# rCSL_lcdc_001 register map
Vendor: Texas Instruments
Peripheral module from a debugger description file (folder c674x).
Registers are 32-bit, access not given, reset 0x0 unless marked. A register's access mark holds for its fields unless they carry their own. Offsets are as the file gives them; lines under a group give offsets from that group; [hi:lo] are bit positions; {n}, {i} and the like mark numbered series; 'fields as' and 'values as' point back to an identical list; <NAME> marks a mode.

## LCDC — LCD Controller
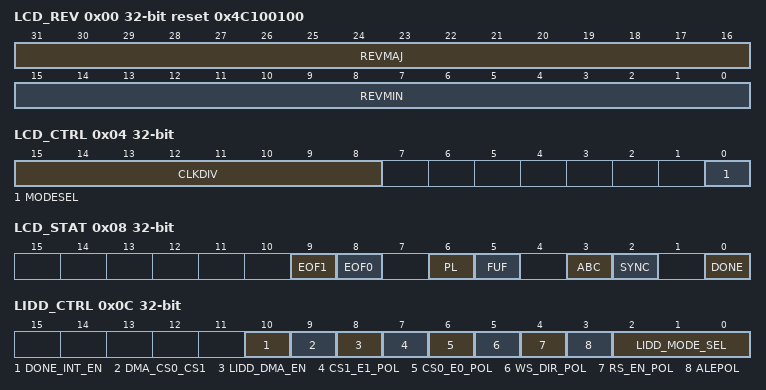
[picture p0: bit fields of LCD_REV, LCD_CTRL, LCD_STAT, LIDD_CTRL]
0x00 LCD_REV ro reset 0x4C100100 — LCD Revision Identification Register
  [31:16] REVMAJ — Peripheral Identification Number
  [15:0] REVMIN — Peripheral Identification Number
0x04 LCD_CTRL — LCD Control Register
  [15:8] CLKDIV rw — Clock Divisor
  [0] MODESEL rw — LCD Mode Select
    0=LIDD (LCD Controller in LIDD mode); 1=RASTER (LCD Controller in Raster mode)
0x08 LCD_STAT — LCD Status Register
  [9] EOF1 rw — End of Frame 1
    0=NO (No end of frame 1 detected); 1=YES (End of frame 1 detected)
  [8] EOF0 rw — End of Frame 0
    0=NO (No end of frame 0 detected); 1=YES (End of frame 0 detected)
  [6] PL rw — Loaded Palette
    0=NO (The palette is not loaded); 1=YES (The palette is loaded)
  [5] FUF rw — FIFO Underflow Status
    0=NO (FIFO has not underrun); 1=YES (LCD dither logic not supplying data to FIFO at a sufficient rate, FIFO has completely emptied and data pin driver logic has attempted to take added data from FIFO)
  [3] ABC rw — AC Bias Count Status
    0=NOT_ZERO (AC bias transition counter has not decremented to zero); 1=ZERO (AC bias transition counter has decremented to zero, indicating that the lcd_ac_o line has transitioned the number of times which is specified by the acbi control bit-field. Counter is reloaded with value in acbi but is disabled until the user clears ABC)
  [2] SYNC rw — Sync Lost
    0=NORMAL; 1=SYNC_LOST (Frame Synchronization Lost has occurred)
  [0] DONE rw — Raster or LIDD Frame Done (shared; depends on whether Raster or LIDD mode enabled)
    0=ENABLE (Raster or DMA-to-LIDD engine is enabled); 1=DISABLE (Raster or DMA-to-LIDD engine is disabled and the active frame has just completed)
0x0C LIDD_CTRL — LCD LIDD Control Register
  [10] DONE_INT_EN rw — LIDD Frame Done Interrupt Enable
    0=DISABLE (Disable LIDD Frame Done interrupt); 1=ENABLE (Enable LIDD Frame Done interrupt (seen on LCD Status Reg bit 0))
  [9] DMA_CS0_CS1 rw — CS0 CS1 Select for LIDD DMA writes
    0=WRITE_CS0 (DMA writes to LIDD CS0); 1=WRITE_CS1 (DMA writes to LIDD CS1)
  [8] LIDD_DMA_EN rw — LIDD DMA Enable
    0=DISABLE (Deactivate DMA control of LIDD interface; DMA control is released upon completion of transfer of the currentframe of data (LIDD Frame Done) after this bit is cleared. The MPU has direct read/write access to the panel in this mode); 1=ENABLE (Activate DMA to drive LIDD interface to support streaming data to smart panels. The MPU cannot access the panel directly in this mode)
  [7] CS1_E1_POL rw — Chip Select 1/Enable 1 (Secondary) Polarity Control
    0=INVERT_DISABLE (Do Not Invert Chip Select 1/Enable 1); 1=INVERT_ENABLE (Invert Chip Select 1/Enable 1 Chip Select 1 is active low by default; Enable 1 is active high by default)
  [6] CS0_E0_POL rw — Chip Select 0/Enable 0 (Primary) Polarity Control
    0=INVERT_DISABLE (Do Not Invert Chip Select 0/Enable 0); 1=INVERT_ENABLE (Invert Chip Select 0/Enable 0 Chip Select 0 is active low by default; Enable 0 is active high by default)
  [5] WS_DIR_POL rw — Write Strobe/Direction Polarity Control
    0=INVERT_DISABLE (Do Not Invert Write Strobe/Direction); 1=INVERT_ENABLE (Invert Write Strobe/Direction Write Strobe/Direction is active low/write low by default)
  [4] RS_EN_POL rw — Read Strobe/Enable Polarity Control
    0=INVERT_DISABLE (Do Not Invert Read Strobe/Enable); 1=INVERT_ENABLE (Invert Read Strobe/Enable Read Strobe is active low by default; Enable is active high by default)
  [3] ALEPOL rw — Address Latch Enable (ALE) Polarity Control
    0=INVERT_DISABLE (Do Not Invert ALE); 1=INVERT_ENABLE (Invert ALE ALE is active low by default)
  [2:0] LIDD_MODE_SEL rw — LIDD Mode Select. Selects type of LCD display interface for the LIDD to drive LIDD Mode Select defines the function of LCD external pins as follows ------------------------------------------------------------------------------------ PIN 000b 001b 010b 011b 100b ------------------------------------------------------------------------------------ lcd_cp En En Rs Rs N/A lcd_lp Dir Dir Ws Ws Dir lcd_fp Ale Ale Ale Ale Ale lcd_ac Cs0 Cs0 Cs0 Cs0 E0 lcd_mclk Mclk Cs1 Mclk Cs1 E1
    0=SYNC_MPU68; 1=ASYNC_MPU68; 2=SYNC_MPU80; 3=ASYNC_MPU80; 4=HITACHI (Hitachi (Async))
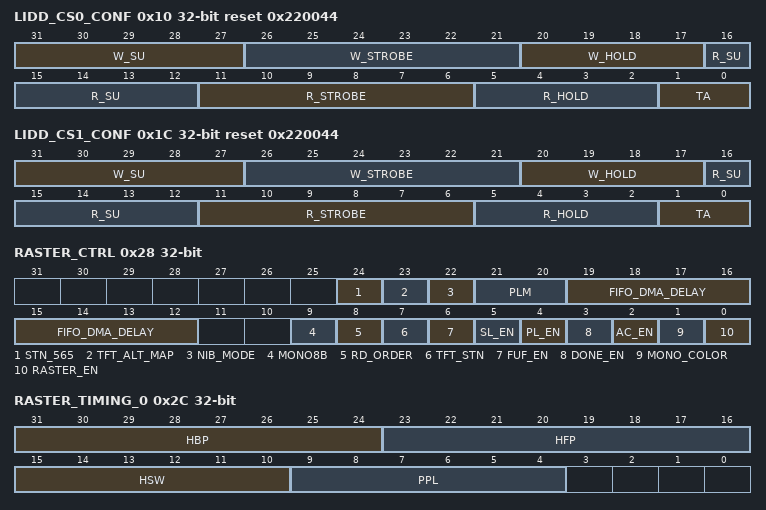
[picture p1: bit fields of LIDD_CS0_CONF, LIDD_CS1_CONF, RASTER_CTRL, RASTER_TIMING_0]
0x10 LIDD_CS0_CONF rw reset 0x220044 — LCD LIDD CS0 Configuration Register
  [31:27] W_SU — Write Strobe Set-Up cycles Field value defines number of memclk cycles after Data Bus/Pad Output Enable, ALE, Direction bit and Chip Select 0 have been set-up before the Write Strobe is asserted when performing a write access
  [26:21] W_STROBE — Write Strobe Duration cycles Field value defines number of memclk cycles for which the Write Strobe is held active when performing a write access
  [20:17] W_HOLD — Write Strobe Hold cycles Field value defines number of memclk cycles for which Data Bus/Pad Output Enable, ALE, Direction bit and Chip Select 0 are held after the Write Strobe is deasserted when performing a write access
  [16:12] R_SU — Read Strobe Set-Up cycles Field value defines number of memclk cycles after Data Bus/Pad Output Enable, ALE, Direction bit and Chip Select 0 have been set-up before the Read Strobe is asserted when performing a read access
  [11:6] R_STROBE — Read Strobe Duration cycles Field value defines number of memclk cycles for which the Read Strobe is held active when performing a read access
  [5:2] R_HOLD — Read Strobe Hold cycles Field value defines number of memclk cycles for which Data Bus/Pad Output Enable, ALE, Direction bit and Chip Select 0 are held after the Read Strobe is deasserted when performing a read access
  [1:0] TA — Field value defines number of memclk cycles between the end of one CS0 device access and the start of another CS0 device access unless the two accesses are both reads, in which case this delay is not incurred
0x14 LIDD_CS0_ADDR — LCD LIDD CS0 Address Read/Write Register
  [15:0] ADR_INDX rw — Peripheral Device Address/ Index value. On writes this field is loaded into the CS0 peripheral device's address generator . On reads this field contains the CS0 peripheral device's status.
0x18 LIDD_CS0_DATA — LCD LIDD CS0 Data Read/Write Register
  [15:0] DATA rw — Peripheral Device Data value. On writes this field is loaded into CS0 peripheral device. On reads this field contains the CS0 peripheral device's data .
0x1C LIDD_CS1_CONF rw reset 0x220044 — LCD LIDD CS1 Configuration Register
  [31:27] W_SU — Write Strobe Set-Up cycles Field value defines number of memclk cycles after Data Bus/Pad Output Enable, ALE, Direction bit and Chip Select 1 have been set-up before the Write Strobe is asserted when performing a write access
  [26:21] W_STROBE — Write Strobe Duration cycles Field value defines number of memclk cycles for which the Write Strobe is held active when performing a write access
  [20:17] W_HOLD — Write Strobe Hold cycles Field value defines number of memclk cycles for which Data Bus/Pad Output Enable, ALE, Direction bit and Chip Select 1 are held after the Write Strobe is deasserted when performing a write access
  [16:12] R_SU — Read Strobe Set-Up cycles Field value defines number of memclk cycles after Data Bus/Pad Output Enable, ALE, Direction bit and Chip Select 1 have been set-up before the Read Strobe is asserted when performing a read access
  [11:6] R_STROBE — Read Strobe Duration cycles Field value defines number of memclk cycles for which the Read Strobe is held active when performing a read access
  [5:2] R_HOLD — Read Strobe Hold cycles Field value defines number of memclk cycles for which Data Bus/Pad Output Enable, ALE, Direction bit and Chip Select 1 are held after the Read Strobe is deasserted when performing a read access
  [1:0] TA — Field value defines number of memclk cycles between the end of one CS1 device access and the start of another CS1 device access unless the two accesses are both reads, in which case this delay is not incurred
0x20 LIDD_CS1_ADDR — LCD LIDD CS1 Address Read/Write Register
  [15:0] ADR_INDX rw — Peripheral Device Address/Index value On writes this field is loaded into the CS1 peripheral device's address generator . On reads this field contains the CS1 peripheral device's status.
0x24 LIDD_CS1_DATA — LCD LIDD CS1 Data Read/Write Register
  [15:0] DATA rw — Peripheral Device Data value On writes this field is loaded into CS1 peripheral device. On reads this field contains the CS1 peripheral device's data .
0x28 RASTER_CTRL — LCD Raster Control Register
  [24] STN_565 rw — 12 BPP (5-6-5) mode
    0=DISABLE (off); 1=ENABLE (on (16 bit data in frame buffer, but only 12 bits are dithered and sent out))
  [23] TFT_ALT_MAP rw — TFT Alternate Signal Mapping
    0=444_DATA (output pixel data for 1, 2, 4, and 8 bpp modes will be right aligned on lcd_pins (11:0)); 1=565_DATA (output pixel data for 1, 2, 4, and 8 bpp will be converted to 5,6,5 format and use pins (15:0) R3 R2 R1 R0 R3 G3 G2 G1 G0 G3 G2 B3 B2 B1 B0 B3)
  [22] NIB_MODE rw — Nibble Mode
    0=DISABLE (Nibble mode is disabled); 1=ENABLE (Nibble mode is enabled)
  [21:20] PLM rw — Palette Loading Mode
    0=PALETTE_DATA (Palette and data loading ( reset value)); 1=PALETTE (Palette loading); 2=DATA (Data loading); 2=DONOT_USE
  [19:12] FIFO_DMA_DELAY rw — FIFO DMA Request Delay Encoded value (0-255) used to specify the number of memory controller clocks the input FIFO DMA request should be disabled. The clock count starts after 16 words read in the input FIFO. Programming reqdly=00h disables this function
  [9] MONO8B rw — Mono 8-bit Mode
    0=4DATA_PIN (LCD_P[3:0] is used to output four bits each LCD_PCLK.); 1=8DATA_PIN (LCD_P[7:0] is used to output eight bits each LCD_PCLK. This bit is ignored in all other modes.)
  [8] RD_ORDER rw — Raster Data Order Select
    0=LSBTOMSB (Frame buffer data is ordered from least-to-most significant bit/nibble/byte/halfword); 1=MSBTOLSB (Frame buffer data is ordered from most-to-least significant bit/nibble/byte/halfword)
  [7] TFT_STN rw — LCD TFT
    0=STN (Passive or STN display operation enabled, dither logic is enabled); 1=TFT (Active or TFT display operation enabled, external palette and DAC required, dither logic bypassed, pin timing changes to support continuous pixel clock, output enable, vsync and hsync)
  [6] FUF_EN rw — FIFO Underflow Interrupt Enable
    0=DISABLE (Disable the FIFO Underflow interrupt.); 1=ENABLE (Enable the FIFO Underflow interrupt.)
  [5] SL_EN rw — Sync Lost Interrupt Enable
    0=DISABLE (Disable the Sync Lost interrupt.); 1=ENABLE (Enable the Sync Lost interrupt.)
  [4] PL_EN rw — Palette Loaded Interrupt Enable
    0=DISABLE (Disable the Palette Loaded interrupt.); 1=ENABLE (Enable the Palette Loaded interrupt.)
  [3] DONE_EN rw — Frame Done Interrupt Enable
    0=DISABLE (Disable the Frame Done interrupt.); 1=ENABLE (Enable the Frame Done interrupt.)
  [2] AC_EN rw — AC Bias Count Interrupt Enable
    0=DISABLE (Disable the AC Bias Count interrupt.); 1=ENABLE (Enable AC Bias Count interrupt.)
  [1] MONO_COLOR rw — LCD Monochrome
    0=COLOR (Color operation enabled); 1=MONOCHROME (Monochrome operation enabled)
  [0] RASTER_EN rw — LCD Raster Controller Enable
    0=DISABLE (Disable the LCD Raster controller.); 1=ENABLE (Enable the LCD Raster controller.le)
0x2C RASTER_TIMING_0 — LCD Raster Timing 0 Register
  [31:24] HBP rw — Horizontal Back Porch Encoded value(from 1-256) is used to specify number of pixel clock periods to add to the beginning of a line transmission before the first set of pixels is output to the display ( program to value minus one). Note that pixel clock is held in its inactive state during the beginning of line wait period in passive display mode and is permitted to transition in active display mode.
  [23:16] HFP rw — Horizontal Front Porch Encoded value(from 1-256) is used to specify number of pixel clock periods to add to the end of a line transmission before the first set of pixels is output to the display ( program to value minus one). Note that pixel clock is held in its inactive state during the end of line wait period in passive display mode and is permitted to transition in active display mode.
  [15:10] HSW rw — Horizontal Sync Pulse Width Encoded value(from 1-64) is used to specify number of pixel clock periods to pulse the line clock at the end of each line(program to value minus one). Note that pixel clcok is held in its inactive state during the generation of the line clock in passive display mode and is permitted to transition in active display mode.
  [9:4] PPL rw — Pixels-per-line This value specifies the number of pixel transmissions per line. Number of Pixels Per Line = ((PPL + 1) * 16) Pixels Per Line Time = (((Pixel Clock) * (PPL + 1)) * 16)
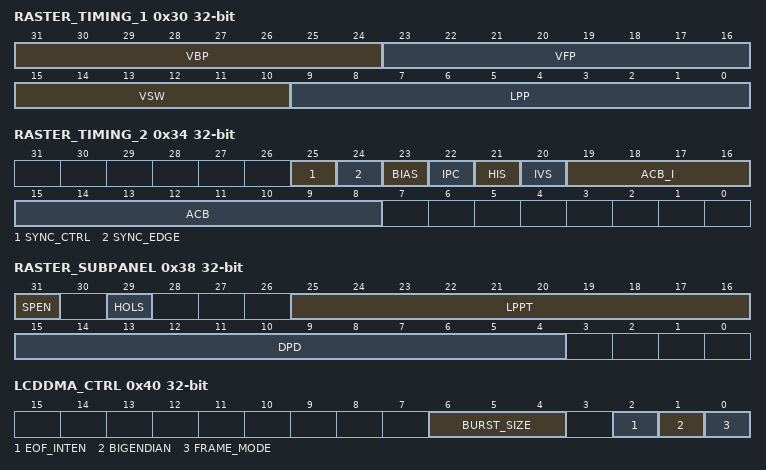
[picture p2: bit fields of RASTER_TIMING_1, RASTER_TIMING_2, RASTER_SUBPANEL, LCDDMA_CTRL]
0x30 RASTER_TIMING_1 rw — LCD Raster Timing 1 Register
  [31:24] VBP — Vertical Back Porch Value (from 0-255) is used to specify number of line clock periods to add to the beginning of a frame before the first set of pixels is output to the display . Note that the line clock transisitons during insertion of the extra line clcock periods.
  [23:16] VFP — Vertical Front Porch Value (from 0-255) is used to specify number of line clock periods to add to the end of each frame. Note that the line clock transisitons during insertion of the extra line clcock periods.
  [15:10] VSW — Vertical Sync Pulse Width In active mode (lcdtft = 1) , encoded value (from 1-64) used to specify numebr of line clock periods to pulse the lcd_fp pin at the end of each frame after the end of frame wait (vfp) period elapses. Frame clock used as VSYNC signal in active mode. In passive mode (lcdtft = 0) , encoded value (from 1-64) used to specify numebr of extra line clock periods to insert after the vertical front porch (vfp) period has elapsed . Note that the width of lcd_fp is not effected by vsw in passive mode, and that line clock transitions during the insertionof the extra line clock periods (program to value minus one)
  [9:0] LPP — Pixels-per-line Encoded value(from 1-1024) used to specify number of lines per panel. It represents the total number of lines on the LCD (program to value minus one)
0x34 RASTER_TIMING_2 — LCD Raster Timing 2 Register
  [25] SYNC_CTRL rw — Hsync/Vsync Pixel Clock Control On/Off Should be ON only when in TFT mode
    0=INACTIVE (lcd_lp and lcd_fp are driven on opposite edges of pixel clock than the lcd_pixel_o); 1=ACTIVE (lcd_lp and lcd_fp are driven according to bit 24)
  [24] SYNC_EDGE rw — Program Hsync/Vsync Rise or Fall
    0=RISING (lcd_lp and lcd_fp are driven on rising edge of pixel clock. (bit 25 must be set to 1)); 1=FALLING (lcd_lp and lcd_fp are driven on falling edge of pixel clock. (bit 25 must be set to 1))
  [23] BIAS rw — Invert Output Enable
    0=ACTIVE_HIGH (lcd_ac pin is active high in active display mode); 1=ACTIVE_LOW (lcd_ac pin is active low in active display mode . In active display mode data driven out to the LCD's data lines on programmed pixel clcok edge when AC-bias is active. Note that IEO is ignored in passive diplay mode.)
  [22] IPC rw — Invert Pixel Clock
    0=RISING (Data is driven on the LCD's data lines on the rising edge of lcd_lp.); 1=FALLING (Data is driven on the LCD's data lines on the falling edge of lcd_lp.)
  [21] HIS rw — Invert Hsync
    0=ACTIVE_HIGH (lcd_lp pin is active high and inactive low); 1=ACTIVE_LOW (lcd_lp pin is active low and inactive high Active and passive mode: horizontal sync pulse/line clock active between lines, after end of line wait period)
  [20] IVS rw — Invert Vsync
    0=ACTIVE_HIGH (lcd_fp pin is active high and inactive low); 1=ACTIVE_LOW (lcd_fp pin is active low and inactive high Active mode: vertical sync pulse active between frames, after end of frame wait period Passive mode: frame clock active during first line of each frame)
  [19:16] ACB_I rw — AC Bias Pin Transitions per Interrupt Value (from 0-255) used to specify the numebr of AC Bias pin transitions to count before setting the line count status (lcd) bit, signalling an interrupt request. Counter is frozen when lcs is set and is restarted when lcs is cleared by software. This function is disabled when acbi = 0x0000
  [15:8] ACB rw — AC Bias Pin Pin Frequency Value (from 0-255) used to specify the number of line clocks to count before transitioning the AC Bias pin. This pin is used to periodically invert the polarity of the power supply to prevent DC charge build-up within the display. acb: Number of line clocks/toggle of the lcd_ac pin
0x38 RASTER_SUBPANEL — LCD Raster Sub-panel Display Register
  [31] SPEN rw — Sub Panel Enable
    0=DISABLE (function disabled); 1=ENABLE (sub-panel function mode enabled)
  [29] HOLS rw — High or Low Signal This field indicates the position of sub-panel compared to LPPT value.
    0=LOW; 1=HIGH
  [25:16] LPPT rw — Line Per Panel threshold This field defines the number of lines to be refreshed (1-1024)
  [15:4] DPD rw — Default Pixel Data DPD defines the default value of the pixel data sent to the panel for the lines until LPPT is reached or after passing the LPPT
0x40 LCDDMA_CTRL — LCD DMA Control Register
  [6:4] BURST_SIZE rw — Burst Size setting for DMA transfers (all DMA transfers are 32 bits wide)
  [2] EOF_INTEN rw — End of Frame interrupt enable Setting this bit allows the End of Frame 0 or 1 Status bits in the LCD Status Register to trigger an interrupt
    0=DISABLE (End of Frame 0/1Interrupt disabled); 1=ENABLE (End of Frame 0/1Interrupt enabled)
  [1] BIGENDIAN rw — Big Endian enable Use this bit when the processor is operating in Big Endian mode and writes to the frame buffer(s) are less than 32 bits wide; only in this scenario we need to change the byte alignment for data coming into the FIFO from the frame buffer(s)
    0=DISABLE (Big Endian data reordering disabled); 1=ENABLE (Big Endian data reordering enabled)
  [0] FRAME_MODE rw
    0=ONE_FB (one frame buffer (FB0 only) used); 1=TWO_FB (two frame buffers used; DMA ping-pongs between FB0 and FB1 in this mode)
0x44 LCDDMA_FB0_BASE rw — LCD DMA Frame Buffer 0 Base Address Register
  [31:0] FB0_BASE — Frame Buffer 0 Base Address pointer. Note: 2 LSB bits are hardwired to 00b
0x48 LCDDMA_FB0_CEILING rw — LCD DMA Frame Buffer 0 Ceiling Address Register
  [31:0] FB0_CEIL — Frame Buffer 0 Ceiling Address pointer. Note: 2 LSB bits are hardwired to 00b
0x4C LCDDMA_FB1_BASE rw — LCD DMA Frame Buffer 1 Base Address Register
  [31:0] FB1_BASE — Frame Buffer 1 Base Address pointer. Note: 2 LSB bits are hardwired to 00b
0x50 LCDDMA_FB1_CEILING rw — LCD DMA Frame Buffer 1 Ceiling Address Register
  [31:0] FB1_CEIL — Frame Buffer 1 Ceiling Address pointer. Note: 2 LSB bits are hardwired to 00b
